# sysresources_secure register map
Vendor: Texas Instruments
Peripheral module from a debugger description file (folder CC35X1).
Registers are 32-bit, access per field, reset 0x0 unless marked. A register's access mark holds for its fields unless they carry their own. Offsets are as the file gives them; lines under a group give offsets from that group; [hi:lo] are bit positions; {n}, {i} and the like mark numbered series; 'fields as' and 'values as' point back to an identical list; <NAME> marks a mode.

## sysresources_secure
0x08 systim_ctrl
  [0] MEM_SYSTIM_ENCLK rw — '1' - enable the reqeusets for the systim clk
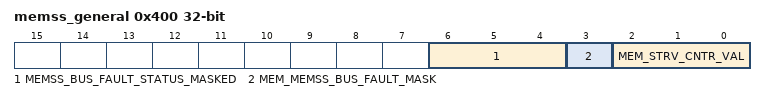
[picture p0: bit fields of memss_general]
0x400 memss_general
  [6:4] MEMSS_BUS_FAULT_STATUS_MASKED ro — '1' - Mask '0' - Do not mask
  [3] MEM_MEMSS_BUS_FAULT_MASK rw — '1' - Mask '0' - Do not mask
  [2:0] MEM_STRV_CNTR_VAL rw — HOST to config how long writing to mailbox can be delayed
0x404 memss_bus_fault_raw_status ro
  [2:0] MEMSS_BUS_FAULT_STATUS_RAW_RDCL — HOST to config how long writing to mailbox can be delayed
